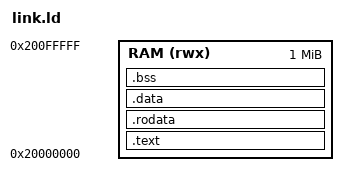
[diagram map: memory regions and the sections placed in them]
OUTPUT_ARCH(riscv)
ENTRY(_start)

MEMORY {
    RAM (rwx) : ORIGIN = 0x20000000, LENGTH = 1M
}

SECTIONS {
    .text : {
        KEEP(*(.text._start))
        *(.text .text.*)
    } > RAM

    .rodata : {
        *(.rodata .rodata.*)
        *(.srodata .srodata.*)
    } > RAM

    .data : {
        *(.data .data.*)
        *(.sdata .sdata.*)
    } > RAM

    .bss : {
        *(.bss .bss.*)
        *(.sbss .sbss.*)
        *(COMMON)
    } > RAM

    __stack_top = ORIGIN(RAM) + LENGTH(RAM);
}
